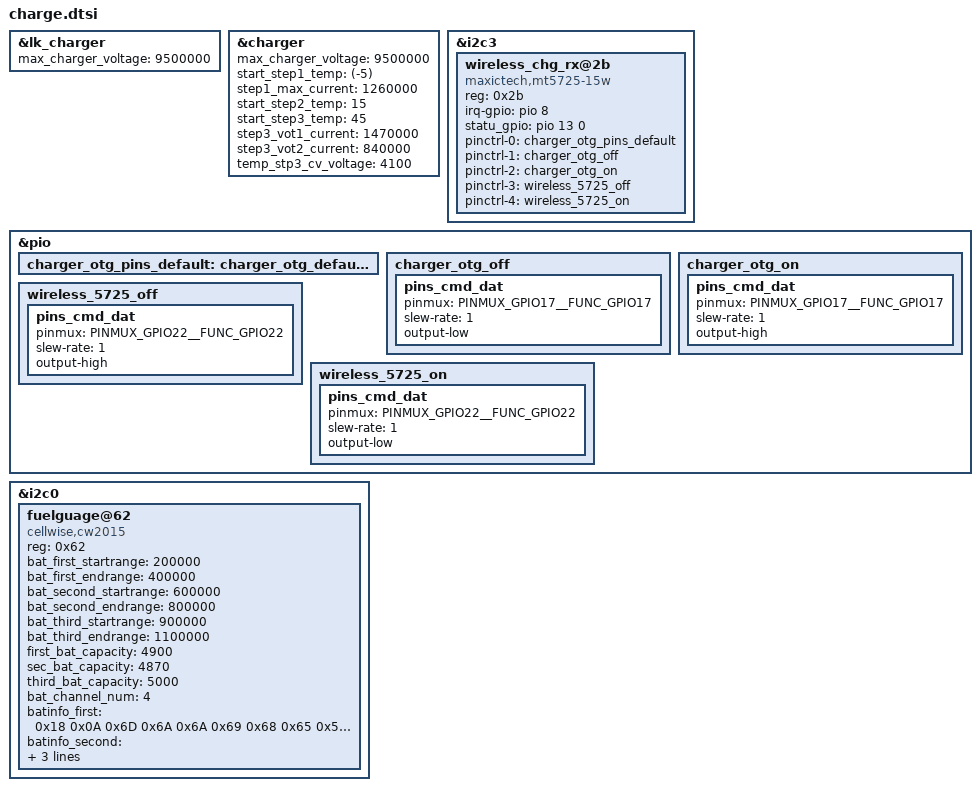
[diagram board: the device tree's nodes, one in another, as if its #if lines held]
&lk_charger{
#if defined(CONFIG_PRIZE_MT5725_SUPPORT_15W)
      max_charger_voltage = <9500000>;
#endif
};
&charger {
#if defined(CONFIG_PRIZE_MT5725_SUPPORT_15W)
      max_charger_voltage = <9500000>;
#endif
#if defined(CONFIG_PRIZE_CHARGE_CURRENT_CTRL_GIGAST)
	  start_step1_temp = <(-5)>;
	  step1_max_current = <1260000>;
	  start_step2_temp = <15>;
	  start_step3_temp = <45>;
	  step3_vot1_current = <1470000>;
	  step3_vot2_current = <840000>;
      temp_stp3_cv_voltage = <4100>;
#endif
};

/* prize sunshuai 20200427 add for 5725 15W wireless charge start */
#if defined(CONFIG_PRIZE_MT5725_SUPPORT_15W)
&i2c3 {
		wireless_chg_rx@2b {
		compatible = "maxictech,mt5725-15w";
		reg = <0x2b>;
		irq-gpio = <&pio 8 0>;//W_CHARGE_INT
		statu_gpio = <&pio 13 0>;
		pinctrl-names = "default", "charger_otg_off", "charger_otg_on",
		           "wireless_5725_off", "wireless_5725_on";
		pinctrl-0 = <&charger_otg_pins_default>;
		pinctrl-1 = <&charger_otg_off>;
		pinctrl-2 = <&charger_otg_on>;
		pinctrl-3 = <&wireless_5725_off>;
		pinctrl-4 = <&wireless_5725_on>;
		status = "okay";
	};
};

&pio {
        charger_otg_pins_default: charger_otg_default {
        };

        charger_otg_off:  charger_otg_off {
            pins_cmd_dat {
                        pinmux = <PINMUX_GPIO17__FUNC_GPIO17>;
                        slew-rate = <1>;
                        output-low;
                };
        };
        charger_otg_on:  charger_otg_on {
            pins_cmd_dat {
                        pinmux = <PINMUX_GPIO17__FUNC_GPIO17>;
                        slew-rate = <1>;
                        output-high;
                };
        };
		wireless_5725_off:  wireless_5725_off {
            pins_cmd_dat {
                        pinmux = <PINMUX_GPIO22__FUNC_GPIO22>;
                        slew-rate = <1>;
                        output-high;
                };
        };
		
        wireless_5725_on:  wireless_5725_on {
            pins_cmd_dat {
                        pinmux = <PINMUX_GPIO22__FUNC_GPIO22>;
                        slew-rate = <1>;
                        output-low;
                };
        };
};
#endif
/* prize sunshuai 20200427 add for 5725 15W wireless charge end */

/*
 * Copyright (C) 2019 prize sunshuai.
 * get cw2015 battery info from dts
 */
&i2c0 {
	fuelguage@62 {
		compatible = "cellwise,cw2015";
		reg = <0x62>;
/* prize-add-sunshuai-2015 Multi-Battery Solution-20200222-start */
#ifdef CONFIG_MTK_CW2015_BATTERY_ID_AUXADC
		bat_first_startrange = <200000>;
		bat_first_endrange = <400000>;
		bat_second_startrange = <600000>;
		bat_second_endrange = <800000>;
		bat_third_startrange = <900000>;
		bat_third_endrange = <1100000>;
		first_bat_capacity = <4900>;
		sec_bat_capacity = <4870>;
		third_bat_capacity = <5000>;
		bat_channel_num = <4>;
#endif
/* prize-add-sunshuai-2015 Multi-Battery Solution-20200222-end */

/* prize-add-sunshuai-2015 Multi-Battery Solution-20200222-start */
#ifdef CONFIG_MTK_CW2015_BATTERY_ID_AUXADC
        batinfo_first = /bits/ 8 <0x18 0x0A 0x6D 0x6A 0x6A 0x69 0x68 0x65 0x5F 0x63 0x60 0x54 0x61 0x5B 0x47 0x41
                    0x37 0x2F 0x29 0x26 0x28 0x33 0x43 0x50 0x24 0x4E 0x0B 0x85 0x32 0x52 0x4D 0x5B
					0x68 0x65 0x65 0x65 0x3D 0x1A 0x66 0x5B 0x0C 0x2B 0x2A 0x5E 0x89 0x91 0x94 0x29
					0x50 0x77 0x98 0xA1 0x80 0x8F 0xC2 0xCB 0x2F 0x00 0x64 0xA5 0xB5 0x0E 0x08 0xF9>;
	    batinfo_second = /bits/ 8 <0x18 0x0A 0x6B 0x6B 0x6B 0x6B 0x68 0x67 0x60 0x68 0x5A 0x59 0x63 0x5A 0x48 0x3F
					0x36 0x2F 0x29 0x24 0x28 0x30 0x41 0x4F 0x28 0x4A 0x0B 0x85 0x34 0x55 0x56 0x6F
					0x82 0x7F 0x80 0x81 0x3E 0x19 0x5D 0x57 0x0B 0x36 0x29 0x5A 0x83 0x94 0x99 0x0D
					0x29 0x7A 0x96 0xA8 0x80 0x95 0xAA 0xCB 0x2F 0x00 0x64 0xA5 0xB5 0x0E 0x08 0xB9>;
	    batinfo_default = /bits/ 8 <0x18 0x0A 0x6D 0x6A 0x6A 0x69 0x68 0x65 0x5F 0x63 0x60 0x54 0x61 0x5B 0x47 0x41
                    0x37 0x2F 0x29 0x26 0x28 0x33 0x43 0x50 0x24 0x4E 0x0B 0x85 0x32 0x52 0x4D 0x5B
					0x68 0x65 0x65 0x65 0x3D 0x1A 0x66 0x5B 0x0C 0x2B 0x2A 0x5E 0x89 0x91 0x94 0x29
					0x50 0x77 0x98 0xA1 0x80 0x8F 0xC2 0xCB 0x2F 0x00 0x64 0xA5 0xB5 0x0E 0x08 0xF9>;
#else
		batinfo = /bits/ 8 <0x18 0x0A 0x6A 0x68 0x6A 0x6A 0x69 0x66 0x64 0x61 0x60 0x5B 0x60 0x56 0x49 0x41
					0x39 0x31 0x2A 0x27 0x2A 0x32 0x40 0x4D 0x2C 0x4B 0x0B 0x85 0x27 0x48 0x4D 0x63
					0x71 0x70 0x72 0x74 0x3F 0x19 0x7B 0x4E 0x0B 0x24 0x1F 0x4F 0x80 0x95 0x9C 0x16
					0x30 0x76 0x96 0xA5 0x80 0x95 0xB9 0xCB 0x2F 0x00 0x64 0xA5 0xB5 0x0E 0x08 0xB1>;
#endif
/* prize-add-sunshuai-2015 Multi-Battery Solution-20200222-end */
	};
};


